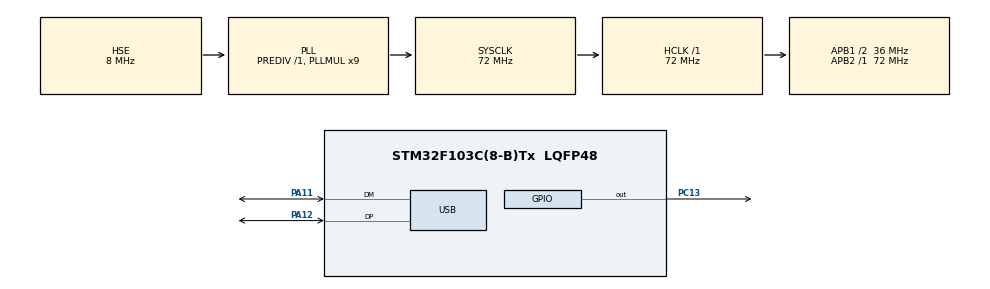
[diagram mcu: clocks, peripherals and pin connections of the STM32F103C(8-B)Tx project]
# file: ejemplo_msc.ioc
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Mcu.Family=STM32F1
Mcu.Name=STM32F103C(8-B)Tx
Mcu.Package=LQFP48
NVIC.PriorityGroup=NVIC_PRIORITYGROUP_4
NVIC.USB_LP_CAN1_RX0_IRQn=true\:0\:0\:false\:false\:true\:false\:true
PA11.Mode=Device
PA11.Signal=USB_DM
PA12.Mode=Device
PA12.Signal=USB_DP
PA13.Mode=Serial_Wire
PA13.Signal=SYS_JTMS-SWDIO
PA14.Mode=Serial_Wire
PA14.Signal=SYS_JTCK-SWCLK
PC13-TAMPER-RTC.Signal=GPIO_Output
PD0-OSC_IN.Mode=HSE-External-Oscillator
PD0-OSC_IN.Signal=RCC_OSC_IN
PD1-OSC_OUT.Mode=HSE-External-Oscillator
PD1-OSC_OUT.Signal=RCC_OSC_OUT
ProjectManager.HeapSize=0x200
ProjectManager.StackSize=0x400
ProjectManager.TargetToolchain=STM32CubeIDE
RCC.AHBFreq_Value=72000000
RCC.APB1CLKDivider=RCC_HCLK_DIV2
RCC.APB1Freq_Value=36000000
RCC.APB1TimFreq_Value=72000000
RCC.APB2Freq_Value=72000000
RCC.APB2TimFreq_Value=72000000
RCC.HCLKFreq_Value=72000000
RCC.PLLMUL=RCC_PLL_MUL9
RCC.SYSCLKFreq_VALUE=72000000
RCC.SYSCLKSource=RCC_SYSCLKSOURCE_PLLCLK
RCC.USBFreq_Value=48000000
RCC.USBPrescaler=RCC_USBCLKSOURCE_PLL_DIV1_5
USB_DEVICE.CLASS_NAME_FS=MSC
USB_DEVICE.VirtualMode=Msc
USB_DEVICE.VirtualModeFS=Msc_FS
VP_USB_DEVICE_VS_USB_DEVICE_MSC_FS.Mode=MSC_FS
board=custom

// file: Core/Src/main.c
/* USER CODE BEGIN Header */
/**
  ******************************************************************************
  * @file           : main.c
  * @brief          : Main program body
  ******************************************************************************
  * @attention
  *
  * <h2><center>&copy; Copyright (c) 2020 STMicroelectronics.
  * All rights reserved.</center></h2>
  *
  * This software component is licensed by ST under BSD 3-Clause license,
  * the "License"; You may not use this file except in compliance with the
  * License. You may obtain a copy of the License at:
  *                        opensource.org/licenses/BSD-3-Clause
  *
  ******************************************************************************
  */
/* USER CODE END Header */
#include "main.h"
#include "usb_device.h"

/* USER CODE BEGIN Includes */
#include "usbd_msc.h"
#include "diskio.h"
/* USER CODE END Includes */

/* USER CODE BEGIN PTD */

/*
 * Ejemplo de uso de mass storage exponiendo una memoria SD por USB.
 * Conecto la SD al SPI1 del STM32F103C8 en los pines:
 * A4 -> SD_CS
 * A5 -> SD_SCLK
 * A6 -> SD_MISO (Línea con Pull-up) de 4k7
 * A7 -> SD_MOSI
 *
 * El código está basado en ejemploSD de:
 * https://www.campusvirtual.frba.utn.edu.ar/especialidad/mod/resource/view.php?id=168138
 *
 * Es interesante ver que para usar la SD desde el mass storage no hace falta
 * interpretar el disco, sólo se expone físicamente (unidades, tamaño de sectores
 * y cantidad de sectores).
 *
 */

/* USER CODE END PTD */

/* USER CODE BEGIN PV */
extern USBD_HandleTypeDef hUsbDeviceFS;
/* USER CODE END PV */

void SystemClock_Config(void);
static void MX_GPIO_Init(void);

int main(void)
{

  /* MCU Configuration--------------------------------------------------------*/

  /* Reset of all peripherals, Initializes the Flash interface and the Systick. */
  HAL_Init();

  /* Configure the system clock */
  SystemClock_Config();

  /* USER CODE BEGIN SysInit */
  	  disk_initialize(0);
  	  /*
  	   * Si bien la interfaz de disco tiene el callback
  	   * int8_t STORAGE_Init_FS(uint8_t lun) no puedo
  	   * usarlo para inicializar (que sería lo apropiado)
  	   * porque disk_initialize tarda más de 1ms y el sistema
  	   * da de baja al dispositivo. Entonces inicializo la SD
  	   * antes del USB, pero como todo gran poder trae aparejada
  	   * una gran responsabilidad, pasa lo siguiente:
  	   *
  	   * 	*	No puedo cambiar la SD con el microcontrolador funcionando
  	   * 		(esté o no esté con USB)
  	   *
  	   * 	*	Al hardcodear la cantidad de bloques de la memoria no puedo
  	   * 		usar otra memoria que no sea de 8GB (
  	   * 		cambiar #define STORAGE_BLK_NBR 0x1000000 ) por la cantidad
  	   * 		de bloques que corresponda.
  	   *
  	   * 	*	Al usar las funciones de uso a la SD del ejemplo anterior, no
  	   * 		puedo tener más de una unidad. Y no hay que olvidarse de colgar
  	   * 		la funcion   disk_timerproc(); en el systick.
  	   *
  	   */
  /* USER CODE END SysInit */

  /* Initialize all configured peripherals */
  MX_GPIO_Init();
  MX_USB_DEVICE_Init();

  /* Infinite loop */
  while (1)
  {

  }
}

void SystemClock_Config(void)
{
  RCC_OscInitTypeDef RCC_OscInitStruct = {0};
  RCC_ClkInitTypeDef RCC_ClkInitStruct = {0};
  RCC_PeriphCLKInitTypeDef PeriphClkInit = {0};

  /** Initializes the RCC Oscillators according to the specified parameters
  * in the RCC_OscInitTypeDef structure.
  */
  RCC_OscInitStruct.OscillatorType = RCC_OSCILLATORTYPE_HSE;
  RCC_OscInitStruct.HSEState = RCC_HSE_ON;
  RCC_OscInitStruct.HSEPredivValue = RCC_HSE_PREDIV_DIV1;
  RCC_OscInitStruct.HSIState = RCC_HSI_ON;
  RCC_OscInitStruct.PLL.PLLState = RCC_PLL_ON;
  RCC_OscInitStruct.PLL.PLLSource = RCC_PLLSOURCE_HSE;
  RCC_OscInitStruct.PLL.PLLMUL = RCC_PLL_MUL9;
  if (HAL_RCC_OscConfig(&RCC_OscInitStruct) != HAL_OK)
  {
    Error_Handler();
  }
  /** Initializes the CPU, AHB and APB buses clocks
  */
  RCC_ClkInitStruct.ClockType = RCC_CLOCKTYPE_HCLK|RCC_CLOCKTYPE_SYSCLK
                              |RCC_CLOCKTYPE_PCLK1|RCC_CLOCKTYPE_PCLK2;
  RCC_ClkInitStruct.SYSCLKSource = RCC_SYSCLKSOURCE_PLLCLK;
  RCC_ClkInitStruct.AHBCLKDivider = RCC_SYSCLK_DIV1;
  RCC_ClkInitStruct.APB1CLKDivider = RCC_HCLK_DIV2;
  RCC_ClkInitStruct.APB2CLKDivider = RCC_HCLK_DIV1;

  if (HAL_RCC_ClockConfig(&RCC_ClkInitStruct, FLASH_LATENCY_2) != HAL_OK)
  {
    Error_Handler();
  }
  PeriphClkInit.PeriphClockSelection = RCC_PERIPHCLK_USB;
  PeriphClkInit.UsbClockSelection = RCC_USBCLKSOURCE_PLL_DIV1_5;
  if (HAL_RCCEx_PeriphCLKConfig(&PeriphClkInit) != HAL_OK)
  {
    Error_Handler();
  }
}

static void MX_GPIO_Init(void)
{
  GPIO_InitTypeDef GPIO_InitStruct = {0};

  /* GPIO Ports Clock Enable */
  __HAL_RCC_GPIOC_CLK_ENABLE();
  __HAL_RCC_GPIOD_CLK_ENABLE();
  __HAL_RCC_GPIOA_CLK_ENABLE();

  /*Configure GPIO pin Output Level */
  HAL_GPIO_WritePin(GPIOC, GPIO_PIN_13, GPIO_PIN_RESET);

  /*Configure GPIO pin : PC13 */
  GPIO_InitStruct.Pin = GPIO_PIN_13;
  GPIO_InitStruct.Mode = GPIO_MODE_OUTPUT_PP;
  GPIO_InitStruct.Pull = GPIO_NOPULL;
  GPIO_InitStruct.Speed = GPIO_SPEED_FREQ_LOW;
  HAL_GPIO_Init(GPIOC, &GPIO_InitStruct);

}

void Error_Handler(void)
{
}

/************************ (C) COPYRIGHT STMicroelectronics *****END OF FILE****/
